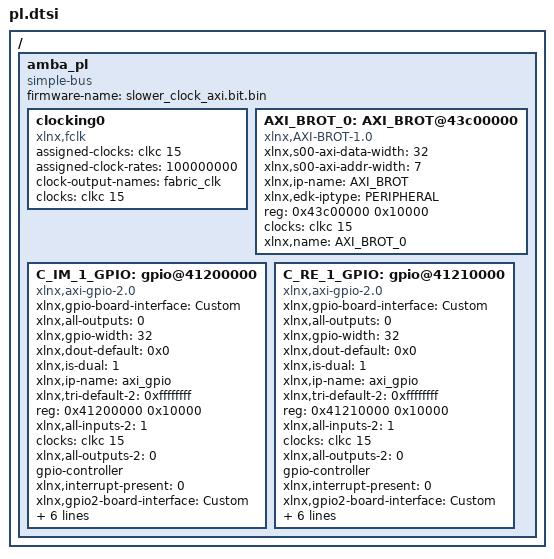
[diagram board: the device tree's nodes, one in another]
/ {
	amba_pl: amba_pl {
		ranges;
		compatible = "simple-bus";
		#address-cells = <1>;
		#size-cells = <1>;
		firmware-name = "slower_clock_axi.bit.bin";
		clocking0: clocking0 {
			compatible = "xlnx,fclk";
			assigned-clocks = <&clkc 15>;
			assigned-clock-rates = <100000000>;
			#clock-cells = <0>;
			clock-output-names = "fabric_clk";
			clocks = <&clkc 15>;
		};
		AXI_BROT_0: AXI_BROT@43c00000 {
			xlnx,s00-axi-data-width = <32>;
			compatible = "xlnx,AXI-BROT-1.0";
			status = "okay";
			clock-names = "s00_axi_aclk";
			xlnx,s00-axi-addr-width = <7>;
			xlnx,ip-name = "AXI_BROT";
			xlnx,edk-iptype = "PERIPHERAL";
			reg = <0x43c00000 0x10000>;
			clocks = <&clkc 15>;
			xlnx,name = "AXI_BROT_0";
		};
		C_IM_1_GPIO: gpio@41200000 {
			xlnx,gpio-board-interface = "Custom";
			compatible = "xlnx,axi-gpio-2.0" , "xlnx,xps-gpio-1.00.a";
			xlnx,all-outputs = <0>;
			#gpio-cells = <2>;
			xlnx,gpio-width = <32>;
			xlnx,dout-default = <0x0>;
			xlnx,is-dual = <1>;
			xlnx,ip-name = "axi_gpio";
			xlnx,tri-default-2 = <0xffffffff>;
			reg = <0x41200000 0x10000>;
			xlnx,all-inputs-2 = <1>;
			clocks = <&clkc 15>;
			xlnx,all-outputs-2 = <0>;
			gpio-controller;
			xlnx,interrupt-present = <0>;
			xlnx,gpio2-board-interface = "Custom";
			xlnx,edk-iptype = "PERIPHERAL";
			xlnx,dout-default-2 = <0x0>;
			status = "okay";
			xlnx,gpio2-width = <32>;
			clock-names = "s_axi_aclk";
			xlnx,tri-default = <0xffffffff>;
			xlnx,name = "C_IM_1_GPIO";
			xlnx,all-inputs = <1>;
		};
		C_RE_1_GPIO: gpio@41210000 {
			xlnx,gpio-board-interface = "Custom";
			compatible = "xlnx,axi-gpio-2.0" , "xlnx,xps-gpio-1.00.a";
			xlnx,all-outputs = <0>;
			#gpio-cells = <2>;
			xlnx,gpio-width = <32>;
			xlnx,dout-default = <0x0>;
			xlnx,is-dual = <1>;
			xlnx,ip-name = "axi_gpio";
			xlnx,tri-default-2 = <0xffffffff>;
			reg = <0x41210000 0x10000>;
			xlnx,all-inputs-2 = <1>;
			clocks = <&clkc 15>;
			xlnx,all-outputs-2 = <0>;
			gpio-controller;
			xlnx,interrupt-present = <0>;
			xlnx,gpio2-board-interface = "Custom";
			xlnx,edk-iptype = "PERIPHERAL";
			xlnx,dout-default-2 = <0x0>;
			status = "okay";
			xlnx,gpio2-width = <32>;
			clock-names = "s_axi_aclk";
			xlnx,tri-default = <0xffffffff>;
			xlnx,name = "C_RE_1_GPIO";
			xlnx,all-inputs = <1>;
		};
	};
};
